# GD32F527 register map
File version: 1.0
CPU: CM33 r0p1, little endian, MPU, FPU, 4 interrupt priority bits
Registers are 32-bit, read-write, reset 0x0 unless marked. A register's access mark holds for its fields unless they carry their own. Offsets are from the block's base; [hi:lo] are bit positions; {n}, {i} and the like mark numbered series; 'fields as' and 'values as' point back to an identical list.

## EXMC — External memory controller
Base 0xA0000000
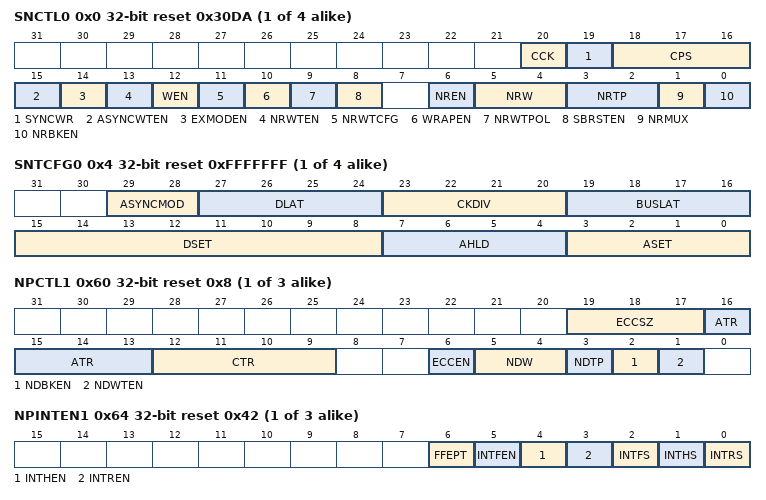
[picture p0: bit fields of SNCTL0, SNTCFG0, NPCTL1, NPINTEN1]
{0x0+8i} SNCTL{i} reset 0x30DA (i=0..3) — SRAM/NOR flash control registe {i}
  [20] CCK — Consecutive clock
  [19] SYNCWR — Synchronous write
  [18:16] CPS — CRAM page size
  [15] ASYNCWTEN — Asynchronous wait enable
  [14] EXMODEN — Extended mode enable
  [13] NRWTEN — NWAIT signal enable
  [12] WEN — Write enable
  [11] NRWTCFG — NWAIT signal configuration, only work in synchronous mode
  [10] WRAPEN — Wrapped burst mode enable
  [9] NRWTPOL — NWAIT signal polarity
  [8] SBRSTEN — Synchronous burst enable
  [6] NREN — NOR Flash access enable
  [5:4] NRW — NOR region memory data bus width
  [3:2] NRTP — NOR region memory type
  [1] NRMUX — NOR region memory address/data multiplexing
  [0] NRBKEN — NOR region enable
{0x4+8i} SNTCFG{i} reset 0xFFFFFFF (i=0..3) — SRAM/NOR flash timing configuration registe {i}
  [29:28] ASYNCMOD — Asynchronous access mode
  [27:24] DLAT — Data latency for NOR Flash. Only valid in synchronous access
  [23:20] CKDIV — Synchronous clock divide ratio. This filed is only effect in synchronous mode.
  [19:16] BUSLAT — Bus latency
  [15:8] DSET — Data setup time
  [7:4] AHLD — Address hold time
  [3:0] ASET — Address setup time
{0x40+0x20*i} NPCTL{i} reset 0x8 (i=1..3) — NAND flash/PC card control registe {i}
  [19:17] ECCSZ — ECC size
  [16:13] ATR — ALE to RE delay
  [12:9] CTR — CLE to RE delay
  [6] ECCEN — ECC enable
  [5:4] NDW — NAND bank memory data bus width
  [3] NDTP — NAND bank memory type
  [2] NDBKEN — NAND bank enable
  [1] NDWTEN — Wait function enable
{0x44+0x20*i} NPINTEN{i} reset 0x42 (i=1..3) — NAND flash/PC card interrupt enable registe {i}
  [6] FFEPT — FIFO empty flag
  [5] INTFEN — Falling edge detection interrupt enable
  [4] INTHEN — High-level detection interrupt enable
  [3] INTREN — Rising edge detection interrupt enable
  [2] INTFS — Falling edge flag
  [1] INTHS — High-level flag
  [0] INTRS — Rsing edge flag
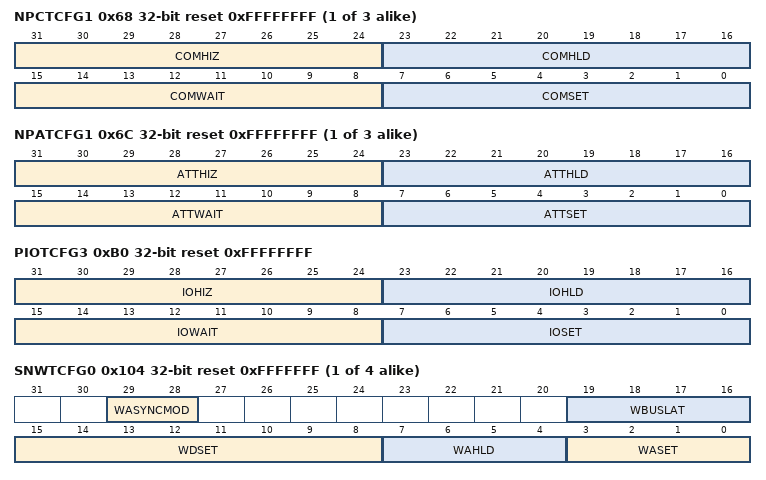
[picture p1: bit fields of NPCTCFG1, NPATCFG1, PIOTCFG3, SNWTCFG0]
{0x48+0x20*i} NPCTCFG{i} reset 0xFFFFFFFF (i=1..3) — NAND flash/PC card common space timing configuration registe {i}
  [31:24] COMHIZ — Common memory data bus HiZ time
  [23:16] COMHLD — Common memory hold time
  [15:8] COMWAIT — Common memory wait time
  [7:0] COMSET — Common memory setup time
{0x4C+0x20*i} NPATCFG{i} reset 0xFFFFFFFF (i=1..3) — NAND flash/PC card attribute space timing configuration registe {i}
  [31:24] ATTHIZ — Attribute memory data bus HiZ time
  [23:16] ATTHLD — Attribute memory hold time
  [15:8] ATTWAIT — Attribute memory wait time
  [7:0] ATTSET — Attribute memory setup time
0x74 NECC1 ro — NAND flash ECC registe 1
  [31:0] ECC — ECC result
0x94 NECC2 ro — NAND flash ECC registe 2
  [31:0] ECC — ECC result
0xB0 PIOTCFG3 reset 0xFFFFFFFF — PC card I/O space timing configuration register
  [31:24] IOHIZ — IO space data bus HiZ time
  [23:16] IOHLD — IO space hold time
  [15:8] IOWAIT — IO space wait time
  [7:0] IOSET — IO space setup time
{0x104+8i} SNWTCFG{i} reset 0xFFFFFFF (i=0..3) — SRAM/NOR flash write timing configuration registe {i}
  [29:28] WASYNCMOD — Asynchronous access mode
  [19:16] WBUSLAT — Bus latency
  [15:8] WDSET — Data setup time
  [7:4] WAHLD — Address hold time
  [3:0] WASET — Address setup time
0x140 SDCTL0 ro reset 0x2D0 — SDRAM control registe 0
  [31:0] ECC — ECC result
0x144 SDCTL1 ro reset 0x2D0 — SDRAM control registe 1
  [31:0] ECC — ECC result
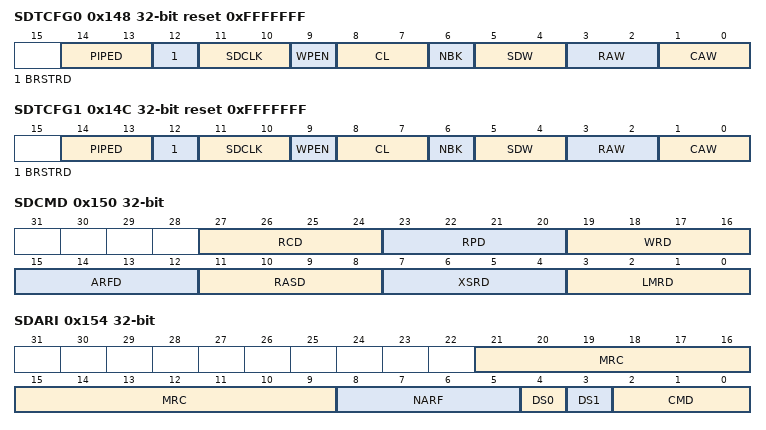
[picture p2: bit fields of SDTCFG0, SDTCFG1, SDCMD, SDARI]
0x148 SDTCFG0 reset 0xFFFFFFF — SDRAM timing configuration registe 0
  [14:13] PIPED — Pipeline delay
  [12] BRSTRD — Burst read
  [11:10] SDCLK — SDRAM clock configuration
  [9] WPEN — Write protection enable
  [8:7] CL — CAS Latency
  [6] NBK — Number of banks
  [5:4] SDW — SDRAM data bus width.
  [3:2] RAW — Row address bit width
  [1:0] CAW — Column address bit width
0x14C SDTCFG1 reset 0xFFFFFFF — SDRAM timing configuration registe 1
  fields as SDTCFG0
0x150 SDCMD — SDRAM command register
  [27:24] RCD — Row to column delay
  [23:20] RPD — Row precharge delay
  [19:16] WRD — Write recovery delay
  [15:12] ARFD — Auto refresh delay
  [11:8] RASD — Row address select delay
  [7:4] XSRD — Exit self-refresh delay
  [3:0] LMRD — Load mode register delay
0x154 SDARI — SDRAM auto-refresh interval register
  [21:9] MRC — Mode register content
  [8:5] NARF — Number of successive auto-refresh
  [4] DS0 — Device select 0
  [3] DS1 — Device select 1
  [2:0] CMD — Command
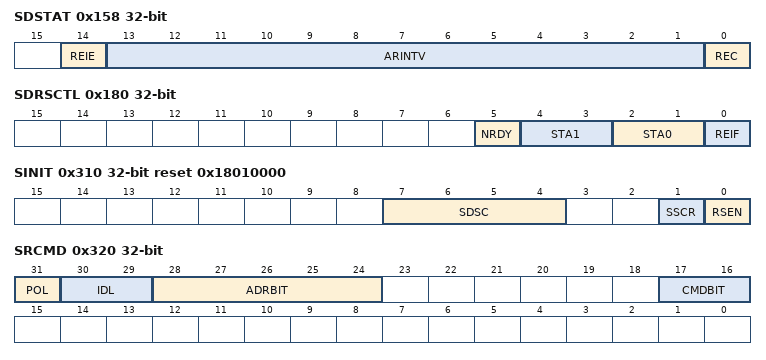
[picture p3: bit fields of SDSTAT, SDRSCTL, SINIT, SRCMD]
0x158 SDSTAT access per field — SDRAM status register
  [14] REIE rw — Refresh error interrupt enable
  [13:1] ARINTV rw — Auto-refresh interval
  [0] REC wo — Refresh error flag clear
0x180 SDRSCTL ro — SDRAM read sample control register
  [5] NRDY — Not ready status
  [4:3] STA1 — Device1 status
  [2:1] STA0 — Device 0 status
  [0] REIF — Refresh error interrupt flag
{0x300+4i} SNLATDEC{i} (i=0..3) — SRAM/NOR flash data latency decrease registe {i}
  [2:0] LATDEC — Data latency decrease for NOR Flash. Only valid in synchronous read access.
0x310 SINIT reset 0x18010000 — SPI initialization registe
  [7:4] SDSC — Select the delayed sample clock of read data
  [1] SSCR — Select sample cycle of read data
  [0] RSEN — Read sample enable
0x320 SRCMD — SPI read command registe
  [31] POL — Read data sample polarity.
  [30:29] IDL — SPI PSRAM ID Length.
  [28:24] ADRBIT — Bit number of SPI PSRAM address phase.
  [17:16] CMDBIT — Bit number of SPI PSRAM command phase
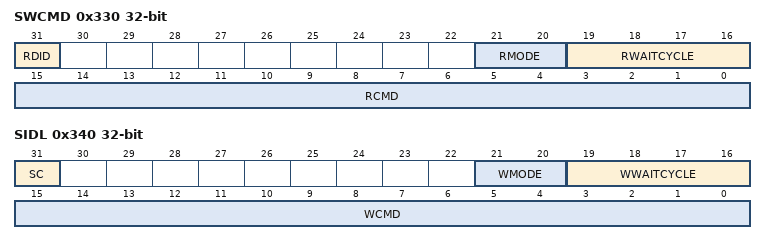
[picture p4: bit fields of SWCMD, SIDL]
0x330 SWCMD — SPI write command registe
  [31] RDID — Send SPI Read ID Command, command code and mode come from RCMD and RMODE.
  [21:20] RMODE — SPI PSRAM read command mode
  [19:16] RWAITCYCLE — SPI read wait cycle number after address phase.
  [15:0] RCMD — SPI read command for AHB read transfer.
0x340 SIDL — SPI ID low registe
  [31] SC — Send SPI special command which does not have address and data phase, command code and mode come from WCMD and WMODE.
  [21:20] WMODE — SPI PSRAM write command mode
  [19:16] WWAITCYCLE — SPI write wait cycle number after address phase
  [15:0] WCMD — SPI write command for AHB write transfer
0x350 SIDH — SPI ID high registe
  [31:0] SIDL — ID low data saved for SPI read ID command
